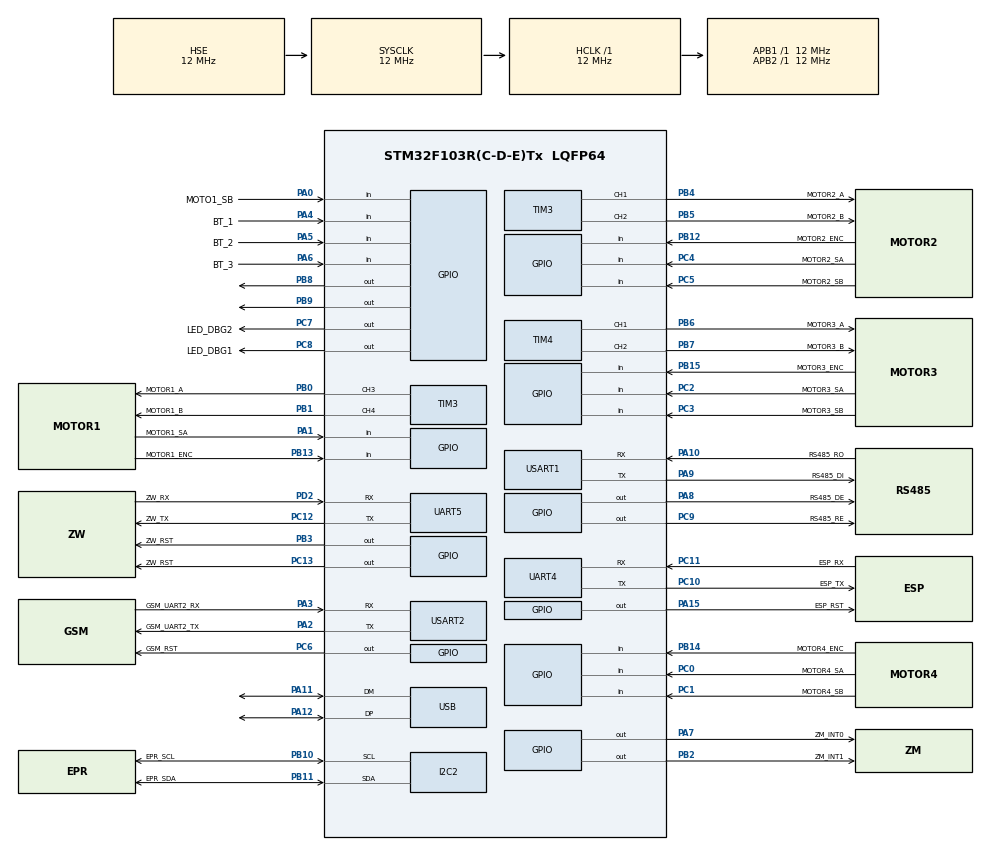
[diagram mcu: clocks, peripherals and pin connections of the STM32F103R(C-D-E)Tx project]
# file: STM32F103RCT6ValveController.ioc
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Mcu.Family=STM32F1
Mcu.Name=STM32F103R(C-D-E)Tx
Mcu.Package=LQFP64
NVIC.PriorityGroup=NVIC_PRIORITYGROUP_4
NVIC.USB_LP_CAN1_RX0_IRQn=true\:0\:0\:false\:false\:true\:false\:true
PA0-WKUP.GPIO_Label=MOTO1_SB
PA0-WKUP.Signal=GPIO_Input
PA1.GPIO_Label=MOTOR1_SA
PA1.Signal=GPIO_Input
PA10.GPIO_Label=RS485_RO
PA10.Mode=Asynchronous
PA10.Signal=USART1_RX
PA11.Mode=Device
PA11.Signal=USB_DM
PA12.Mode=Device
PA12.Signal=USB_DP
PA13.Mode=Serial_Wire
PA13.Signal=SYS_JTMS-SWDIO
PA14.Mode=Serial_Wire
PA14.Signal=SYS_JTCK-SWCLK
PA15.GPIO_Label=ESP_RST
PA15.Signal=GPIO_Output
PA2.GPIO_Label=GSM_UART2_TX
PA2.Mode=Asynchronous
PA2.Signal=USART2_TX
PA3.GPIO_Label=GSM_UART2_RX
PA3.Mode=Asynchronous
PA3.Signal=USART2_RX
PA4.GPIO_Label=BT_1
PA4.Signal=GPIO_Input
PA5.GPIO_Label=BT_2
PA5.Signal=GPIO_Input
PA6.GPIO_Label=BT_3
PA6.Signal=GPIO_Input
PA7.GPIO_Label=ZM_INT0
PA7.Signal=GPIO_Output
PA8.GPIO_Label=RS485_DE
PA8.Signal=GPIO_Output
PA9.GPIO_Label=RS485_DI
PA9.Mode=Asynchronous
PA9.Signal=USART1_TX
PB0.GPIO_Label=MOTOR1_A
PB0.Signal=S_TIM3_CH3
PB1.GPIO_Label=MOTOR1_B
PB1.Signal=S_TIM3_CH4
PB10.GPIO_Label=EPR_SCL
PB10.Mode=I2C
PB10.Signal=I2C2_SCL
PB11.GPIO_Label=EPR_SDA
PB11.Mode=I2C
PB11.Signal=I2C2_SDA
PB12.GPIO_Label=MOTOR2_ENC
PB12.Signal=GPIO_Input
PB13.GPIO_Label=MOTOR1_ENC
PB13.Signal=GPIO_Input
PB14.GPIO_Label=MOTOR4_ENC
PB14.Signal=GPIO_Input
PB15.GPIO_Label=MOTOR3_ENC
PB15.Signal=GPIO_Input
PB2.GPIO_Label=ZM_INT1
PB2.Signal=GPIO_Output
PB3.GPIO_Label=ZW_RST
PB3.Signal=GPIO_Output
PB4.GPIO_Label=MOTOR2_A
PB4.Signal=S_TIM3_CH1
PB5.GPIO_Label=MOTOR2_B
PB5.Signal=S_TIM3_CH2
PB6.GPIO_Label=MOTOR3_A
PB6.Signal=S_TIM4_CH1
PB7.GPIO_Label=MOTOR3_B
PB7.Signal=S_TIM4_CH2
PB8.Signal=GPIO_Output
PB9.Signal=GPIO_Output
PC0.GPIO_Label=MOTOR4_SA
PC0.Signal=GPIO_Input
PC1.GPIO_Label=MOTOR4_SB
PC1.Signal=GPIO_Input
PC10.GPIO_Label=ESP_TX
PC10.Mode=Asynchronous
PC10.Signal=UART4_TX
PC11.GPIO_Label=ESP_RX
PC11.Mode=Asynchronous
PC11.Signal=UART4_RX
PC12.GPIO_Label=ZW_TX
PC12.Mode=Asynchronous
PC12.Signal=UART5_TX
PC13-TAMPER-RTC.GPIO_Label=ZW_RST
PC13-TAMPER-RTC.Signal=GPIO_Output
PC2.GPIO_Label=MOTOR3_SA
PC2.Signal=GPIO_Input
PC3.GPIO_Label=MOTOR3_SB
PC3.Signal=GPIO_Input
PC4.GPIO_Label=MOTOR2_SA
PC4.Signal=GPIO_Input
PC5.GPIO_Label=MOTOR2_SB
PC5.Signal=GPIO_Input
PC6.GPIO_Label=GSM_RST
PC6.Signal=GPIO_Output
PC7.GPIO_Label=LED_DBG2
PC7.Signal=GPIO_Output
PC8.GPIO_Label=LED_DBG1
PC8.Signal=GPIO_Output
PC9.GPIO_Label=RS485_RE
PC9.Signal=GPIO_Output
PD0-OSC_IN.Mode=HSE-External-Oscillator
PD0-OSC_IN.Signal=RCC_OSC_IN
PD1-OSC_OUT.Mode=HSE-External-Oscillator
PD1-OSC_OUT.Signal=RCC_OSC_OUT
PD2.GPIO_Label=ZW_RX
PD2.Mode=Asynchronous
PD2.Signal=UART5_RX
ProjectManager.HeapSize=0x200
ProjectManager.StackSize=0x400
ProjectManager.TargetToolchain=SW4STM32
RCC.AHBFreq_Value=12000000
RCC.APB1Freq_Value=12000000
RCC.APB1TimFreq_Value=12000000
RCC.APB2Freq_Value=12000000
RCC.APB2TimFreq_Value=12000000
RCC.HCLKFreq_Value=12000000
RCC.HSE_VALUE=12000000
RCC.PLLMUL=RCC_PLL_MUL4
RCC.SYSCLKFreq_VALUE=12000000
RCC.SYSCLKSource=RCC_SYSCLKSOURCE_HSE
RCC.USBFreq_Value=48000000
SH.S_TIM3_CH1.0=TIM3_CH1,PWM Generation1 CH1
SH.S_TIM3_CH2.0=TIM3_CH2,PWM Generation2 CH2
SH.S_TIM3_CH3.0=TIM3_CH3,PWM Generation3 CH3
SH.S_TIM3_CH4.0=TIM3_CH4,PWM Generation4 CH4
SH.S_TIM4_CH1.0=TIM4_CH1,PWM Generation1 CH1
SH.S_TIM4_CH2.0=TIM4_CH2,PWM Generation2 CH2
TIM3.Channel-PWM\ Generation1\ CH1=TIM_CHANNEL_1
TIM3.Channel-PWM\ Generation2\ CH2=TIM_CHANNEL_2
TIM3.Channel-PWM\ Generation3\ CH3=TIM_CHANNEL_3
TIM3.Channel-PWM\ Generation4\ CH4=TIM_CHANNEL_4
TIM4.Channel-PWM\ Generation1\ CH1=TIM_CHANNEL_1
TIM4.Channel-PWM\ Generation2\ CH2=TIM_CHANNEL_2
UART4.VirtualMode=Asynchronous
UART5.VirtualMode=Asynchronous
USART1.VirtualMode=VM_ASYNC
USART2.VirtualMode=VM_ASYNC
USB_DEVICE.CLASS_NAME_FS=CDC
USB_DEVICE.VirtualMode=Cdc
USB_DEVICE.VirtualModeFS=Cdc_FS
VP_RTC_VS_RTC_Activate.Mode=RTC_Enabled
VP_RTC_VS_RTC_Calendar.Mode=RTC_Calendar
VP_USB_DEVICE_VS_USB_DEVICE_CDC_FS.Mode=CDC_FS
board=custom

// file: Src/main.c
/* USER CODE BEGIN Header */
/**
  ******************************************************************************
  * @file           : main.c
  * @brief          : Main program body
  ******************************************************************************
  * @attention
  *
  * <h2><center>&copy; Copyright (c) 2019 STMicroelectronics.
  * All rights reserved.</center></h2>
  *
  * This software component is licensed by ST under Ultimate Liberty license
  * SLA0044, the "License"; You may not use this file except in compliance with
  * the License. You may obtain a copy of the License at:
  *                             www.st.com/SLA0044
  *
  ******************************************************************************
  */
/* USER CODE END Header */

#include "main.h"
#include "usb_device.h"

I2C_HandleTypeDef hi2c2;

RTC_HandleTypeDef hrtc;

TIM_HandleTypeDef htim3;
TIM_HandleTypeDef htim4;

UART_HandleTypeDef huart4;
UART_HandleTypeDef huart5;
UART_HandleTypeDef huart1;
UART_HandleTypeDef huart2;

void SystemClock_Config(void);
static void MX_GPIO_Init(void);
static void MX_USART1_UART_Init(void);
static void MX_USART2_UART_Init(void);
static void MX_RTC_Init(void);
static void MX_TIM3_Init(void);
static void MX_TIM4_Init(void);
static void MX_UART4_Init(void);
static void MX_UART5_Init(void);
static void MX_I2C2_Init(void);
/* USER CODE BEGIN PFP */
//volatile BOOL Flow_status = FALSE;
//volatile BOOL Zw_connect_Flag = FALSE;
/* USER CODE END PFP */

int main(void)
{
  /* USER CODE BEGIN 1 */
	//val_mode_t Valve_mode = VALVE_IDE;

  /* USER CODE END 1 */

  /* MCU Configuration--------------------------------------------------------*/

  /* Reset of all peripherals, Initializes the Flash interface and the Systick. */
  HAL_Init();

  /* Configure the system clock */
  SystemClock_Config();

  /* Initialize all configured peripherals */
  MX_GPIO_Init();
  MX_USART1_UART_Init();
  MX_USART2_UART_Init();
  MX_RTC_Init();
  MX_TIM3_Init();
  MX_TIM4_Init();
  MX_UART4_Init();
  MX_UART5_Init();
  MX_USB_DEVICE_Init();
  MX_I2C2_Init();
  /* USER CODE BEGIN 2 */
  //ZW_UART_COMMAND uart_cmd;
  uint8_t data;
  uint8_t buf='t';
  //BOOL ZW_ready =FALSE;
  /* USER CODE END 2 */

  /* Infinite loop */
  /* USER CODE BEGIN WHILE */
  while (1)
  {
	  //HAL_I2C_Mem_Write(&hi2c2,0xA0,0x,0x01,&buf,1,100);
	  //HAL_I2C_Master_Transmit(&hi2c2,0xA0,'q',1,10);
	  //HAL_I2C_Master_Receive(&hi2c2,0xA0,&data,1,100);
	  HAL_Delay(1000);
	  HAL_I2C_Mem_Read(&hi2c2,0xA0,0x22,0x01,&data,1,100);
	  HAL_UART_Transmit(&huart2,&data,1,100);
    /* USER CODE END WHILE */
  }
}

void SystemClock_Config(void)
{
  RCC_OscInitTypeDef RCC_OscInitStruct = {0};
  RCC_ClkInitTypeDef RCC_ClkInitStruct = {0};
  RCC_PeriphCLKInitTypeDef PeriphClkInit = {0};

  /** Initializes the CPU, AHB and APB busses clocks
  */
  RCC_OscInitStruct.OscillatorType = RCC_OSCILLATORTYPE_LSI|RCC_OSCILLATORTYPE_HSE;
  RCC_OscInitStruct.HSEState = RCC_HSE_ON;
  RCC_OscInitStruct.HSEPredivValue = RCC_HSE_PREDIV_DIV1;
  RCC_OscInitStruct.HSIState = RCC_HSI_ON;
  RCC_OscInitStruct.LSIState = RCC_LSI_ON;
  RCC_OscInitStruct.PLL.PLLState = RCC_PLL_ON;
  RCC_OscInitStruct.PLL.PLLSource = RCC_PLLSOURCE_HSE;
  RCC_OscInitStruct.PLL.PLLMUL = RCC_PLL_MUL4;
  if (HAL_RCC_OscConfig(&RCC_OscInitStruct) != HAL_OK)
  {
    Error_Handler();
  }
  /** Initializes the CPU, AHB and APB busses clocks
  */
  RCC_ClkInitStruct.ClockType = RCC_CLOCKTYPE_HCLK|RCC_CLOCKTYPE_SYSCLK
                              |RCC_CLOCKTYPE_PCLK1|RCC_CLOCKTYPE_PCLK2;
  RCC_ClkInitStruct.SYSCLKSource = RCC_SYSCLKSOURCE_HSE;
  RCC_ClkInitStruct.AHBCLKDivider = RCC_SYSCLK_DIV1;
  RCC_ClkInitStruct.APB1CLKDivider = RCC_HCLK_DIV1;
  RCC_ClkInitStruct.APB2CLKDivider = RCC_HCLK_DIV1;

  if (HAL_RCC_ClockConfig(&RCC_ClkInitStruct, FLASH_LATENCY_0) != HAL_OK)
  {
    Error_Handler();
  }
  PeriphClkInit.PeriphClockSelection = RCC_PERIPHCLK_RTC|RCC_PERIPHCLK_USB;
  PeriphClkInit.RTCClockSelection = RCC_RTCCLKSOURCE_LSI;
  PeriphClkInit.UsbClockSelection = RCC_USBCLKSOURCE_PLL;
  if (HAL_RCCEx_PeriphCLKConfig(&PeriphClkInit) != HAL_OK)
  {
    Error_Handler();
  }
}

static void MX_I2C2_Init(void)
{

  hi2c2.Instance = I2C2;
  hi2c2.Init.ClockSpeed = 100000;
  hi2c2.Init.DutyCycle = I2C_DUTYCYCLE_2;
  hi2c2.Init.OwnAddress1 = 0;
  hi2c2.Init.AddressingMode = I2C_ADDRESSINGMODE_7BIT;
  hi2c2.Init.DualAddressMode = I2C_DUALADDRESS_DISABLE;
  hi2c2.Init.OwnAddress2 = 0;
  hi2c2.Init.GeneralCallMode = I2C_GENERALCALL_DISABLE;
  hi2c2.Init.NoStretchMode = I2C_NOSTRETCH_DISABLE;
  if (HAL_I2C_Init(&hi2c2) != HAL_OK)
  {
    Error_Handler();
  }

}

static void MX_RTC_Init(void)
{

  RTC_TimeTypeDef sTime = {0};
  RTC_DateTypeDef DateToUpdate = {0};

  /** Initialize RTC Only
  */
  hrtc.Instance = RTC;
  hrtc.Init.AsynchPrediv = RTC_AUTO_1_SECOND;
  hrtc.Init.OutPut = RTC_OUTPUTSOURCE_ALARM;
  if (HAL_RTC_Init(&hrtc) != HAL_OK)
  {
    Error_Handler();
  }

  /** Initialize RTC and set the Time and Date
  */
  sTime.Hours = 0x0;
  sTime.Minutes = 0x0;
  sTime.Seconds = 0x0;

  if (HAL_RTC_SetTime(&hrtc, &sTime, RTC_FORMAT_BCD) != HAL_OK)
  {
    Error_Handler();
  }
  DateToUpdate.WeekDay = RTC_WEEKDAY_MONDAY;
  DateToUpdate.Month = RTC_MONTH_JANUARY;
  DateToUpdate.Date = 0x1;
  DateToUpdate.Year = 0x0;

  if (HAL_RTC_SetDate(&hrtc, &DateToUpdate, RTC_FORMAT_BCD) != HAL_OK)
  {
    Error_Handler();
  }

}

static void MX_TIM3_Init(void)
{

  TIM_MasterConfigTypeDef sMasterConfig = {0};
  TIM_OC_InitTypeDef sConfigOC = {0};

  htim3.Instance = TIM3;
  htim3.Init.Prescaler = 0;
  htim3.Init.CounterMode = TIM_COUNTERMODE_UP;
  htim3.Init.Period = 0;
  htim3.Init.ClockDivision = TIM_CLOCKDIVISION_DIV1;
  htim3.Init.AutoReloadPreload = TIM_AUTORELOAD_PRELOAD_DISABLE;
  if (HAL_TIM_PWM_Init(&htim3) != HAL_OK)
  {
    Error_Handler();
  }
  sMasterConfig.MasterOutputTrigger = TIM_TRGO_RESET;
  sMasterConfig.MasterSlaveMode = TIM_MASTERSLAVEMODE_DISABLE;
  if (HAL_TIMEx_MasterConfigSynchronization(&htim3, &sMasterConfig) != HAL_OK)
  {
    Error_Handler();
  }
  sConfigOC.OCMode = TIM_OCMODE_PWM1;
  sConfigOC.Pulse = 0;
  sConfigOC.OCPolarity = TIM_OCPOLARITY_HIGH;
  sConfigOC.OCFastMode = TIM_OCFAST_DISABLE;
  if (HAL_TIM_PWM_ConfigChannel(&htim3, &sConfigOC, TIM_CHANNEL_1) != HAL_OK)
  {
    Error_Handler();
  }
  if (HAL_TIM_PWM_ConfigChannel(&htim3, &sConfigOC, TIM_CHANNEL_2) != HAL_OK)
  {
    Error_Handler();
  }
  if (HAL_TIM_PWM_ConfigChannel(&htim3, &sConfigOC, TIM_CHANNEL_3) != HAL_OK)
  {
    Error_Handler();
  }
  if (HAL_TIM_PWM_ConfigChannel(&htim3, &sConfigOC, TIM_CHANNEL_4) != HAL_OK)
  {
    Error_Handler();
  }
  HAL_TIM_MspPostInit(&htim3);

}

static void MX_TIM4_Init(void)
{

  TIM_MasterConfigTypeDef sMasterConfig = {0};
  TIM_OC_InitTypeDef sConfigOC = {0};

  htim4.Instance = TIM4;
  htim4.Init.Prescaler = 0;
  htim4.Init.CounterMode = TIM_COUNTERMODE_UP;
  htim4.Init.Period = 0;
  htim4.Init.ClockDivision = TIM_CLOCKDIVISION_DIV1;
  htim4.Init.AutoReloadPreload = TIM_AUTORELOAD_PRELOAD_DISABLE;
  if (HAL_TIM_PWM_Init(&htim4) != HAL_OK)
  {
    Error_Handler();
  }
  sMasterConfig.MasterOutputTrigger = TIM_TRGO_RESET;
  sMasterConfig.MasterSlaveMode = TIM_MASTERSLAVEMODE_DISABLE;
  if (HAL_TIMEx_MasterConfigSynchronization(&htim4, &sMasterConfig) != HAL_OK)
  {
    Error_Handler();
  }
  sConfigOC.OCMode = TIM_OCMODE_PWM1;
  sConfigOC.Pulse = 0;
  sConfigOC.OCPolarity = TIM_OCPOLARITY_HIGH;
  sConfigOC.OCFastMode = TIM_OCFAST_DISABLE;
  if (HAL_TIM_PWM_ConfigChannel(&htim4, &sConfigOC, TIM_CHANNEL_1) != HAL_OK)
  {
    Error_Handler();
  }
  if (HAL_TIM_PWM_ConfigChannel(&htim4, &sConfigOC, TIM_CHANNEL_2) != HAL_OK)
  {
    Error_Handler();
  }
  HAL_TIM_MspPostInit(&htim4);

}

static void MX_UART4_Init(void)
{

  huart4.Instance = UART4;
  huart4.Init.BaudRate = 115200;
  huart4.Init.WordLength = UART_WORDLENGTH_8B;
  huart4.Init.StopBits = UART_STOPBITS_1;
  huart4.Init.Parity = UART_PARITY_NONE;
  huart4.Init.Mode = UART_MODE_TX_RX;
  huart4.Init.HwFlowCtl = UART_HWCONTROL_NONE;
  huart4.Init.OverSampling = UART_OVERSAMPLING_16;
  if (HAL_UART_Init(&huart4) != HAL_OK)
  {
    Error_Handler();
  }

}

static void MX_UART5_Init(void)
{

  huart5.Instance = UART5;
  huart5.Init.BaudRate = 115200;
  huart5.Init.WordLength = UART_WORDLENGTH_8B;
  huart5.Init.StopBits = UART_STOPBITS_1;
  huart5.Init.Parity = UART_PARITY_NONE;
  huart5.Init.Mode = UART_MODE_TX_RX;
  huart5.Init.HwFlowCtl = UART_HWCONTROL_NONE;
  huart5.Init.OverSampling = UART_OVERSAMPLING_16;
  if (HAL_UART_Init(&huart5) != HAL_OK)
  {
    Error_Handler();
  }

}

static void MX_USART1_UART_Init(void)
{

  huart1.Instance = USART1;
  huart1.Init.BaudRate = 115200;
  huart1.Init.WordLength = UART_WORDLENGTH_8B;
  huart1.Init.StopBits = UART_STOPBITS_1;
  huart1.Init.Parity = UART_PARITY_NONE;
  huart1.Init.Mode = UART_MODE_TX_RX;
  huart1.Init.HwFlowCtl = UART_HWCONTROL_NONE;
  huart1.Init.OverSampling = UART_OVERSAMPLING_16;
  if (HAL_UART_Init(&huart1) != HAL_OK)
  {
    Error_Handler();
  }

}

static void MX_USART2_UART_Init(void)
{

  huart2.Instance = USART2;
  huart2.Init.BaudRate = 115200;
  huart2.Init.WordLength = UART_WORDLENGTH_8B;
  huart2.Init.StopBits = UART_STOPBITS_1;
  huart2.Init.Parity = UART_PARITY_NONE;
  huart2.Init.Mode = UART_MODE_TX_RX;
  huart2.Init.HwFlowCtl = UART_HWCONTROL_NONE;
  huart2.Init.OverSampling = UART_OVERSAMPLING_16;
  if (HAL_UART_Init(&huart2) != HAL_OK)
  {
    Error_Handler();
  }

}

static void MX_GPIO_Init(void)
{
  GPIO_InitTypeDef GPIO_InitStruct = {0};

  /* GPIO Ports Clock Enable */
  __HAL_RCC_GPIOC_CLK_ENABLE();
  __HAL_RCC_GPIOD_CLK_ENABLE();
  __HAL_RCC_GPIOA_CLK_ENABLE();
  __HAL_RCC_GPIOB_CLK_ENABLE();

  /*Configure GPIO pin Output Level */
  HAL_GPIO_WritePin(GPIOC, ZW_RST_Pin|GSM_RST_Pin|LED_DBG2_Pin|LED_DBG1_Pin
                          |RS485_RE_Pin, GPIO_PIN_RESET);

  /*Configure GPIO pin Output Level */
  HAL_GPIO_WritePin(GPIOA, ZM_INT0_Pin|RS485_DE_Pin|ESP_RST_Pin, GPIO_PIN_RESET);

  /*Configure GPIO pin Output Level */
  HAL_GPIO_WritePin(GPIOB, ZM_INT1_Pin|ZW_RSTB3_Pin|GPIO_PIN_8|GPIO_PIN_9, GPIO_PIN_RESET);

  /*Configure GPIO pins : ZW_RST_Pin GSM_RST_Pin LED_DBG2_Pin LED_DBG1_Pin
                           RS485_RE_Pin */
  GPIO_InitStruct.Pin = ZW_RST_Pin|GSM_RST_Pin|LED_DBG2_Pin|LED_DBG1_Pin
                          |RS485_RE_Pin;
  GPIO_InitStruct.Mode = GPIO_MODE_OUTPUT_PP;
  GPIO_InitStruct.Pull = GPIO_NOPULL;
  GPIO_InitStruct.Speed = GPIO_SPEED_FREQ_LOW;
  HAL_GPIO_Init(GPIOC, &GPIO_InitStruct);

  /*Configure GPIO pins : MOTOR4_SA_Pin MOTOR4_SB_Pin MOTOR3_SA_Pin MOTOR3_SB_Pin
                           MOTOR2_SA_Pin MOTOR2_SB_Pin */
  GPIO_InitStruct.Pin = MOTOR4_SA_Pin|MOTOR4_SB_Pin|MOTOR3_SA_Pin|MOTOR3_SB_Pin
                          |MOTOR2_SA_Pin|MOTOR2_SB_Pin;
  GPIO_InitStruct.Mode = GPIO_MODE_INPUT;
  GPIO_InitStruct.Pull = GPIO_NOPULL;
  HAL_GPIO_Init(GPIOC, &GPIO_InitStruct);

  /*Configure GPIO pins : MOTO1_SB_Pin MOTOR1_SA_Pin BT_1_Pin BT_2_Pin
                           BT_3_Pin */
  GPIO_InitStruct.Pin = MOTO1_SB_Pin|MOTOR1_SA_Pin|BT_1_Pin|BT_2_Pin
                          |BT_3_Pin;
  GPIO_InitStruct.Mode = GPIO_MODE_INPUT;
  GPIO_InitStruct.Pull = GPIO_NOPULL;
  HAL_GPIO_Init(GPIOA, &GPIO_InitStruct);

  /*Configure GPIO pins : ZM_INT0_Pin RS485_DE_Pin ESP_RST_Pin */
  GPIO_InitStruct.Pin = ZM_INT0_Pin|RS485_DE_Pin|ESP_RST_Pin;
  GPIO_InitStruct.Mode = GPIO_MODE_OUTPUT_PP;
  GPIO_InitStruct.Pull = GPIO_NOPULL;
  GPIO_InitStruct.Speed = GPIO_SPEED_FREQ_LOW;
  HAL_GPIO_Init(GPIOA, &GPIO_InitStruct);

  /*Configure GPIO pins : ZM_INT1_Pin ZW_RSTB3_Pin PB8 PB9 */
  GPIO_InitStruct.Pin = ZM_INT1_Pin|ZW_RSTB3_Pin|GPIO_PIN_8|GPIO_PIN_9;
  GPIO_InitStruct.Mode = GPIO_MODE_OUTPUT_PP;
  GPIO_InitStruct.Pull = GPIO_NOPULL;
  GPIO_InitStruct.Speed = GPIO_SPEED_FREQ_LOW;
  HAL_GPIO_Init(GPIOB, &GPIO_InitStruct);

  /*Configure GPIO pins : MOTOR2_ENC_Pin MOTOR1_ENC_Pin MOTOR4_ENC_Pin MOTOR3_ENC_Pin */
  GPIO_InitStruct.Pin = MOTOR2_ENC_Pin|MOTOR1_ENC_Pin|MOTOR4_ENC_Pin|MOTOR3_ENC_Pin;
  GPIO_InitStruct.Mode = GPIO_MODE_INPUT;
  GPIO_InitStruct.Pull = GPIO_NOPULL;
  HAL_GPIO_Init(GPIOB, &GPIO_InitStruct);

}

void Error_Handler(void)
{
}

/************************ (C) COPYRIGHT STMicroelectronics *****END OF FILE****/
